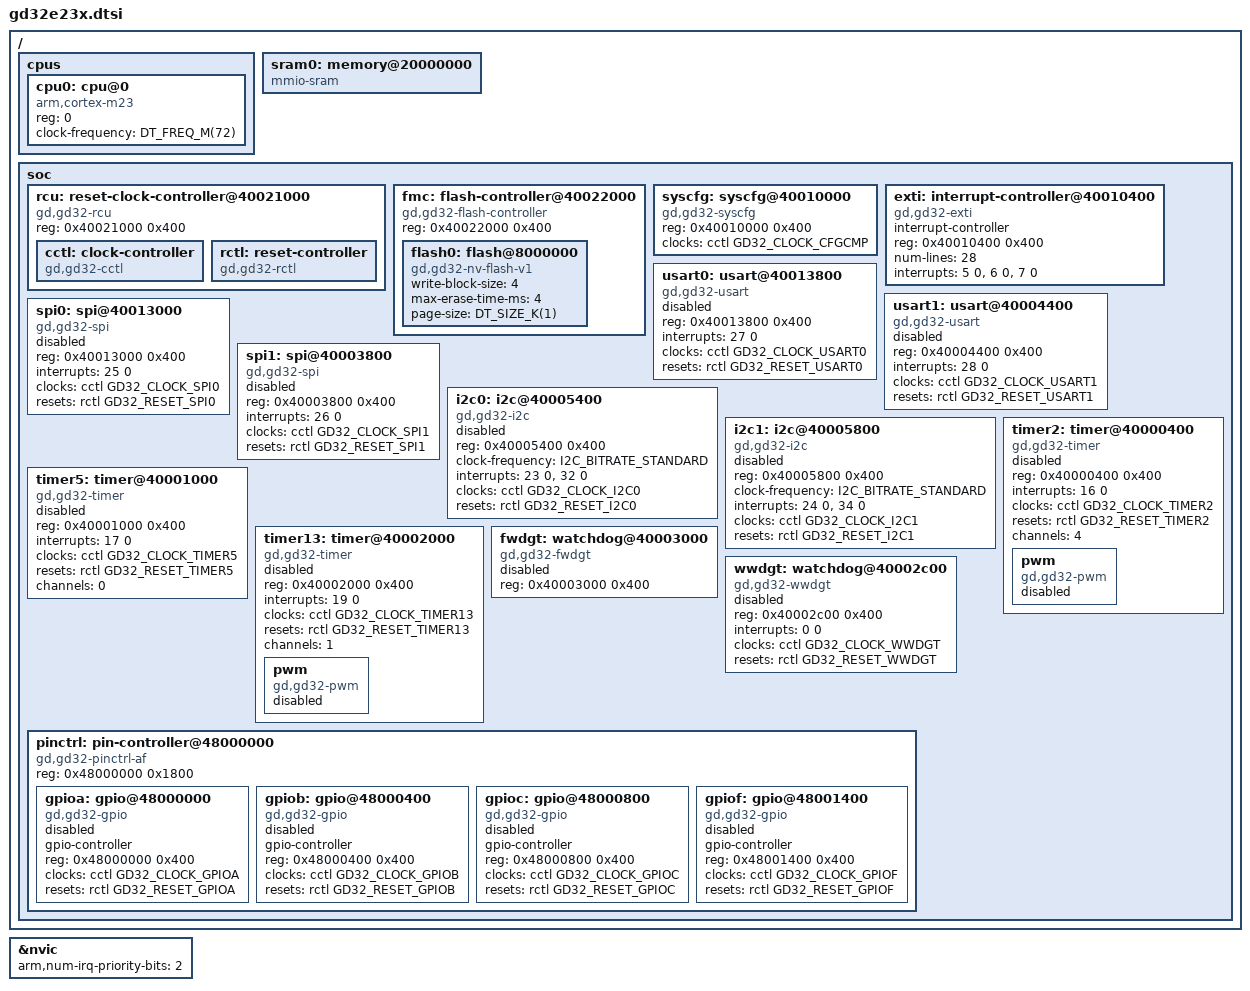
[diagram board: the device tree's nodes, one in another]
/*
 * Copyright (c) 2026 GigaDevice Semiconductor Inc.
 *
 * SPDX-License-Identifier: Apache-2.0
 */

#include <freq.h>
#include <mem.h>
#include <arm/armv8-m.dtsi>
#include <zephyr/dt-bindings/gpio/gpio.h>
#include <zephyr/dt-bindings/i2c/i2c.h>
#include <zephyr/dt-bindings/pwm/pwm.h>
#include <zephyr/dt-bindings/clock/gd32e23x-clocks.h>
#include <zephyr/dt-bindings/reset/gd32e23x.h>

/ {
	cpus {
		#address-cells = <1>;
		#size-cells = <0>;

		cpu0: cpu@0 {
			compatible = "arm,cortex-m23";
			reg = <0>;
			clock-frequency = <DT_FREQ_M(72)>;
		};
	};

	sram0: memory@20000000 {
		compatible = "mmio-sram";
	};

	soc {
		rcu: reset-clock-controller@40021000 {
			compatible = "gd,gd32-rcu";
			reg = <0x40021000 0x400>;
			status = "okay";

			cctl: clock-controller {
				compatible = "gd,gd32-cctl";
				#clock-cells = <1>;
				status = "okay";
			};

			rctl: reset-controller {
				compatible = "gd,gd32-rctl";
				#reset-cells = <1>;
				status = "okay";
			};
		};

		fmc: flash-controller@40022000 {
			compatible = "gd,gd32-flash-controller";
			reg = <0x40022000 0x400>;

			#address-cells = <1>;
			#size-cells = <1>;
			ranges;

			flash0: flash@8000000 {
				compatible = "gd,gd32-nv-flash-v1", "soc-nv-flash";
				write-block-size = <4>;
				max-erase-time-ms = <4>;
				page-size = <DT_SIZE_K(1)>;
			};
		};

		syscfg: syscfg@40010000 {
			compatible = "gd,gd32-syscfg";
			reg = <0x40010000 0x400>;
			clocks = <&cctl GD32_CLOCK_CFGCMP>;
		};

		exti: interrupt-controller@40010400 {
			compatible = "gd,gd32-exti";
			interrupt-controller;
			#interrupt-cells = <1>;
			reg = <0x40010400 0x400>;
			num-lines = <28>;
			interrupts = <5 0>, <6 0>, <7 0>;
			interrupt-names = "line0-1", "line2-3", "line4-15";
			status = "okay";
		};

		usart0: usart@40013800 {
			compatible = "gd,gd32-usart";
			reg = <0x40013800 0x400>;
			interrupts = <27 0>;
			clocks = <&cctl GD32_CLOCK_USART0>;
			resets = <&rctl GD32_RESET_USART0>;
			status = "disabled";
		};

		usart1: usart@40004400 {
			compatible = "gd,gd32-usart";
			reg = <0x40004400 0x400>;
			interrupts = <28 0>;
			clocks = <&cctl GD32_CLOCK_USART1>;
			resets = <&rctl GD32_RESET_USART1>;
			status = "disabled";
		};

		spi0: spi@40013000 {
			compatible = "gd,gd32-spi";
			reg = <0x40013000 0x400>;
			interrupts = <25 0>;
			clocks = <&cctl GD32_CLOCK_SPI0>;
			resets = <&rctl GD32_RESET_SPI0>;
			status = "disabled";
			#address-cells = <1>;
			#size-cells = <0>;
		};

		spi1: spi@40003800 {
			compatible = "gd,gd32-spi";
			reg = <0x40003800 0x400>;
			interrupts = <26 0>;
			clocks = <&cctl GD32_CLOCK_SPI1>;
			resets = <&rctl GD32_RESET_SPI1>;
			status = "disabled";
			#address-cells = <1>;
			#size-cells = <0>;
		};

		i2c0: i2c@40005400 {
			compatible = "gd,gd32-i2c";
			reg = <0x40005400 0x400>;
			#address-cells = <1>;
			#size-cells = <0>;
			clock-frequency = <I2C_BITRATE_STANDARD>;
			interrupts = <23 0>, <32 0>;
			interrupt-names = "event", "error";
			clocks = <&cctl GD32_CLOCK_I2C0>;
			resets = <&rctl GD32_RESET_I2C0>;
			status = "disabled";
		};

		i2c1: i2c@40005800 {
			compatible = "gd,gd32-i2c";
			reg = <0x40005800 0x400>;
			#address-cells = <1>;
			#size-cells = <0>;
			clock-frequency = <I2C_BITRATE_STANDARD>;
			interrupts = <24 0>, <34 0>;
			interrupt-names = "event", "error";
			clocks = <&cctl GD32_CLOCK_I2C1>;
			resets = <&rctl GD32_RESET_I2C1>;
			status = "disabled";
		};

		timer2: timer@40000400 {
			compatible = "gd,gd32-timer";
			reg = <0x40000400 0x400>;
			interrupts = <16 0>;
			interrupt-names = "global";
			clocks = <&cctl GD32_CLOCK_TIMER2>;
			resets = <&rctl GD32_RESET_TIMER2>;
			channels = <4>;
			status = "disabled";

			pwm {
				compatible = "gd,gd32-pwm";
				status = "disabled";
				#pwm-cells = <3>;
			};
		};

		timer5: timer@40001000 {
			compatible = "gd,gd32-timer";
			reg = <0x40001000 0x400>;
			interrupts = <17 0>;
			interrupt-names = "global";
			clocks = <&cctl GD32_CLOCK_TIMER5>;
			resets = <&rctl GD32_RESET_TIMER5>;
			channels = <0>;
			status = "disabled";
		};

		timer13: timer@40002000 {
			compatible = "gd,gd32-timer";
			reg = <0x40002000 0x400>;
			interrupts = <19 0>;
			interrupt-names = "global";
			clocks = <&cctl GD32_CLOCK_TIMER13>;
			resets = <&rctl GD32_RESET_TIMER13>;
			channels = <1>;
			status = "disabled";

			pwm {
				compatible = "gd,gd32-pwm";
				status = "disabled";
				#pwm-cells = <3>;
			};
		};

		fwdgt: watchdog@40003000 {
			compatible = "gd,gd32-fwdgt";
			reg = <0x40003000 0x400>;
			status = "disabled";
		};

		wwdgt: watchdog@40002c00 {
			compatible = "gd,gd32-wwdgt";
			reg = <0x40002c00 0x400>;
			interrupts = <0 0>;
			clocks = <&cctl GD32_CLOCK_WWDGT>;
			resets = <&rctl GD32_RESET_WWDGT>;
			status = "disabled";
		};

		pinctrl: pin-controller@48000000 {
			compatible = "gd,gd32-pinctrl-af";
			reg = <0x48000000 0x1800>;
			#address-cells = <1>;
			#size-cells = <1>;
			status = "okay";

			gpioa: gpio@48000000 {
				compatible = "gd,gd32-gpio";
				gpio-controller;
				#gpio-cells = <2>;
				reg = <0x48000000 0x400>;
				clocks = <&cctl GD32_CLOCK_GPIOA>;
				resets = <&rctl GD32_RESET_GPIOA>;
				status = "disabled";
			};

			gpiob: gpio@48000400 {
				compatible = "gd,gd32-gpio";
				gpio-controller;
				#gpio-cells = <2>;
				reg = <0x48000400 0x400>;
				clocks = <&cctl GD32_CLOCK_GPIOB>;
				resets = <&rctl GD32_RESET_GPIOB>;
				status = "disabled";
			};

			gpioc: gpio@48000800 {
				compatible = "gd,gd32-gpio";
				gpio-controller;
				#gpio-cells = <2>;
				reg = <0x48000800 0x400>;
				clocks = <&cctl GD32_CLOCK_GPIOC>;
				resets = <&rctl GD32_RESET_GPIOC>;
				status = "disabled";
			};

			gpiof: gpio@48001400 {
				compatible = "gd,gd32-gpio";
				gpio-controller;
				#gpio-cells = <2>;
				reg = <0x48001400 0x400>;
				clocks = <&cctl GD32_CLOCK_GPIOF>;
				resets = <&rctl GD32_RESET_GPIOF>;
				status = "disabled";
			};
		};
	};
};

&nvic {
	arm,num-irq-priority-bits = <2>;
};
